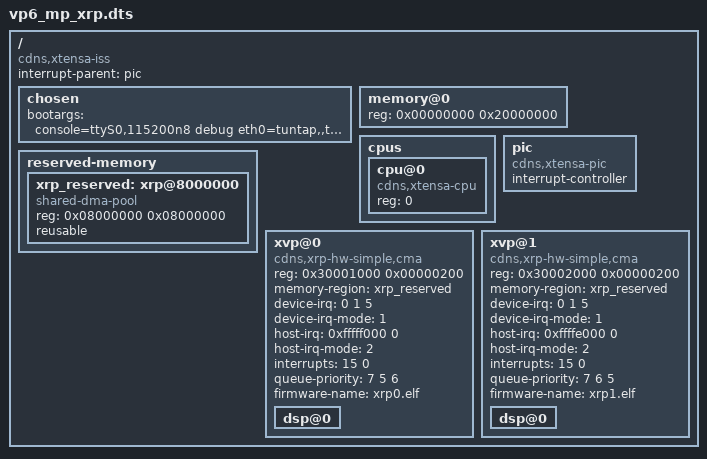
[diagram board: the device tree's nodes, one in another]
/*
 * Copyright (c) 2016 - 2019 Cadence Design Systems Inc.
 *
 * Permission is hereby granted, free of charge, to any person obtaining
 * a copy of this software and associated documentation files (the
 * "Software"), to deal in the Software without restriction, including
 * without limitation the rights to use, copy, modify, merge, publish,
 * distribute, sublicense, and/or sell copies of the Software, and to
 * permit persons to whom the Software is furnished to do so, subject to
 * the following conditions:
 *
 * The above copyright notice and this permission notice shall be included
 * in all copies or substantial portions of the Software.
 *
 * THE SOFTWARE IS PROVIDED "AS IS", WITHOUT WARRANTY OF ANY KIND,
 * EXPRESS OR IMPLIED, INCLUDING BUT NOT LIMITED TO THE WARRANTIES OF
 * MERCHANTABILITY, FITNESS FOR A PARTICULAR PURPOSE AND NONINFRINGEMENT.
 * IN NO EVENT SHALL THE AUTHORS OR COPYRIGHT HOLDERS BE LIABLE FOR ANY
 * CLAIM, DAMAGES OR OTHER LIABILITY, WHETHER IN AN ACTION OF CONTRACT,
 * TORT OR OTHERWISE, ARISING FROM, OUT OF OR IN CONNECTION WITH THE
 * SOFTWARE OR THE USE OR OTHER DEALINGS IN THE SOFTWARE.
 */

/dts-v1/;

/ {
	compatible = "cdns,xtensa-iss";
	#address-cells = <1>;
	#size-cells = <1>;
	interrupt-parent = <&pic>;

	chosen {
		bootargs = "console=ttyS0,115200n8 debug eth0=tuntap,,tap9 root=/dev/simdisk0";
	};

	memory@0 {
		device_type = "memory";
		reg = <0x00000000 0x20000000>;
	};

	cpus {
		#address-cells = <1>;
		#size-cells = <0>;
		cpu@0 {
			compatible = "cdns,xtensa-cpu";
			reg = <0>;
		};
	};

	pic: pic {
		compatible = "cdns,xtensa-pic";
		/* one cell: internal irq number,
		 * two cells: second cell == 0: internal irq number
		 *            second cell == 1: external irq number
		 */
		#interrupt-cells = <2>;
		interrupt-controller;
	};

	reserved-memory {
		#address-cells = <1>;
		#size-cells = <1>;
		ranges;

		xrp_reserved: xrp@8000000 {
			compatible = "shared-dma-pool";
			reg = <0x08000000 0x08000000>;
			reusable;
		};
	};

	xvp@0 {
		#address-cells = <1>;
		#size-cells = <1>;
		compatible = "cdns,xrp-hw-simple,cma";
		reg = <0x30001000 0x00000200>;
		memory-region = <&xrp_reserved>;
		device-irq = <0 1 5>; /* offset, bit#, IRQ# */
		device-irq-mode = <1>;
		host-irq = <0xfffff000 0>; /* offset, bit# */
		host-irq-mode = <2>;
		interrupts = <15 0>;
		queue-priority = <7 5 6>;
		firmware-name = "xrp0.elf";
		ranges = <0x00000000 0x00000000 0x20000000
			  0x3ffc0000 0x20000000 0x00020000
			  0x3ffe0000 0x20020000 0x00020000
			  0x50000000 0x50000000 0x01000000
			  0x60000000 0x60000000 0x20000000>;
		dsp@0 {
		};
	};

	xvp@1 {
		#address-cells = <1>;
		#size-cells = <1>;
		compatible = "cdns,xrp-hw-simple,cma";
		reg = <0x30002000 0x00000200>;
		memory-region = <&xrp_reserved>;
		device-irq = <0 1 5>; /* offset, bit#, IRQ# */
		device-irq-mode = <1>;
		host-irq = <0xffffe000 0>; /* offset, bit# */
		host-irq-mode = <2>;
		interrupts = <15 0>;
		queue-priority = <7 6 5>;
		firmware-name = "xrp1.elf";
		ranges = <0x00000000 0x00000000 0x20000000
			  0x3ffc0000 0x20040000 0x00020000
			  0x3ffe0000 0x20060000 0x00020000
			  0x50000000 0x50000000 0x01000000
			  0x60000000 0x60000000 0x20000000>;
		dsp@0 {
		};
	};

};
